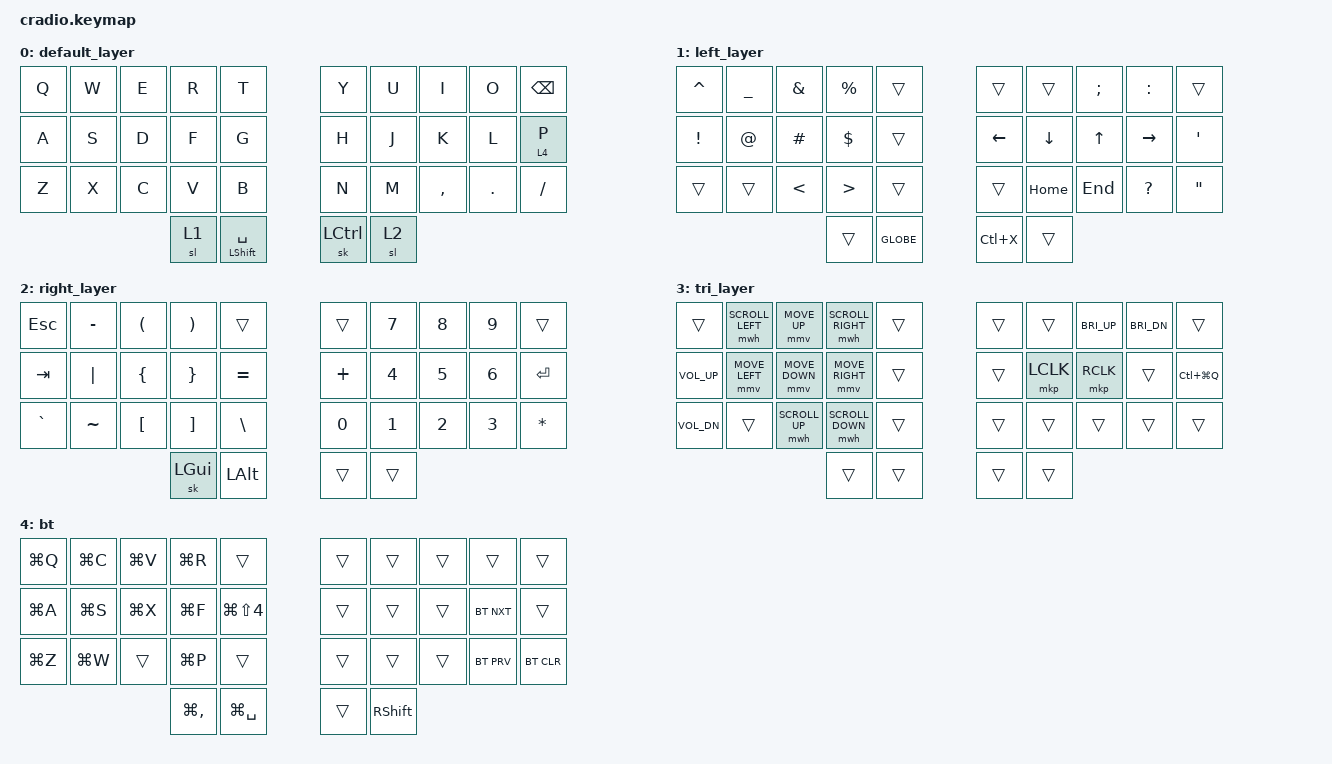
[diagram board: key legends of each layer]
/*
 * Copyright (c) 2020 The ZMK Contributors
 *
 * SPDX-License-Identifier: MIT
 */

#include <behaviors.dtsi>
#include <dt-bindings/zmk/keys.h>
#include <dt-bindings/zmk/bt.h>
#include <dt-bindings/zmk/mouse.h>


&mt {
    flavor = "tap-preferred";
    tapping_term_ms = <200>;
};

&mmv {
    time-to-max-speed-ms = <500>;
    acceleration-exponent=<2>;
};

&mwh {
    time-to-max-speed-ms = <500>;
    acceleration-exponent=<2>;
};


/ {
    combos {
        compatible = "zmk,combos";
        combo_t {
            timeout-ms = <50>;
	    key-positions = <12 13>;
            bindings = <&kp T>;
            layers = <0>;
        };
        combo_b {
            timeout-ms = <50>;
	    key-positions = <11 12>;
            bindings = <&kp B>;
            layers = <0>;
        };
        combo_y {
            timeout-ms = <50>;
	    key-positions = <16 17>;
            bindings = <&kp Y>;
            layers = <0>;
        };
        combo_n {
            timeout-ms = <50>;
	    key-positions = <17 18>;
            bindings = <&kp N>;
            layers = <0>;
        };
    };
    conditional_layers {
        compatible = "zmk,conditional-layers";
        tri_layer {
            if-layers = <1 2>;
            then-layer = <3>;
        };
    };
        keymap {
                compatible = "zmk,keymap";
		default_layer {
		bindings = <
		&kp Q &kp W &kp E &kp R &kp T				&kp Y  &kp U  &kp I     &kp O   &kp BSPC
		&kp A &kp S &kp D &kp F &kp G				&kp H  &kp J  &kp K     &kp L   &lt 4 P
		&kp Z &kp X &kp C &kp V &kp B                           &kp N  &kp M  &kp COMMA &kp DOT &kp SLASH
	            &sl 1 &mt LSHIFT SPACE                               &sk LCTRL &sl 2
		>;
		};

		left_layer {
		bindings = <
		&kp CARET &kp UNDER  &kp AMPS  &kp PERCENT  &trans		&trans   &trans   &kp SEMI &kp COLON &trans
		&kp EXCL  &kp AT     &kp HASH  &kp DOLLAR   &trans		&kp LEFT &kp DOWN &kp UP   &kp RIGHT &kp SQT
		&trans    &trans     &kp LT    &kp GT       &trans	        &trans   &kp HOME &kp END  &kp QMARK &kp DQT
					    &trans &kp GLOBE				&kp LC(X) &trans
		>;
		};

		right_layer {
		bindings = <
		&kp ESC   &kp MINUS &kp LPAR  &kp RPAR  &trans			&trans    &kp N7 &kp N8 &kp N9 &trans
		&kp TAB   &kp PIPE  &kp LBRC  &kp RBRC  &kp EQUAL		&kp PLUS  &kp N4 &kp N5 &kp N6 &kp RET
		&kp GRAVE &kp TILDE &kp LBKT  &kp RBKT  &kp BSLH                &kp N0    &kp N1 &kp N2 &kp N3 &kp STAR
					  &sk LGUI &kp LALT				&trans &trans
		>;
		};

		tri_layer {
		bindings = <
		&trans        &mwh SCROLL_LEFT &mmv MOVE_UP    &mwh SCROLL_RIGHT&trans             &trans  &trans     &kp C_BRI_UP &kp C_BRI_DN &trans
		&kp C_VOL_UP  &mmv MOVE_LEFT   &mmv MOVE_DOWN  &mmv MOVE_RIGHT  &trans             &trans  &mkp LCLK  &mkp RCLK    &trans       &kp LC(LG(Q))
		&kp C_VOL_DN  &trans           &mwh SCROLL_UP  &mwh SCROLL_DOWN &trans             &trans  &trans   &trans       &trans       &trans
					 &trans &trans                                       &trans &trans
		>;
		};
		bt {
		bindings = <
		&kp LG(Q)  &kp LG(C) &kp LG(V) &kp LG(R) &trans                 &trans &trans &trans &trans &trans
		&kp LG(A)  &kp LG(S) &kp LG(X) &kp LG(F) &kp LG(LS(N4))         &trans &trans &trans &bt BT_NXT &trans
		&kp LG(Z)  &kp LG(W) &trans    &kp LG(P) &trans			&trans &trans &trans &bt BT_PRV &bt BT_CLR
					 &kp LG(COMMA) &kp LG(SPACE)			&trans &kp RSHIFT
		>;
		};
	};
};
